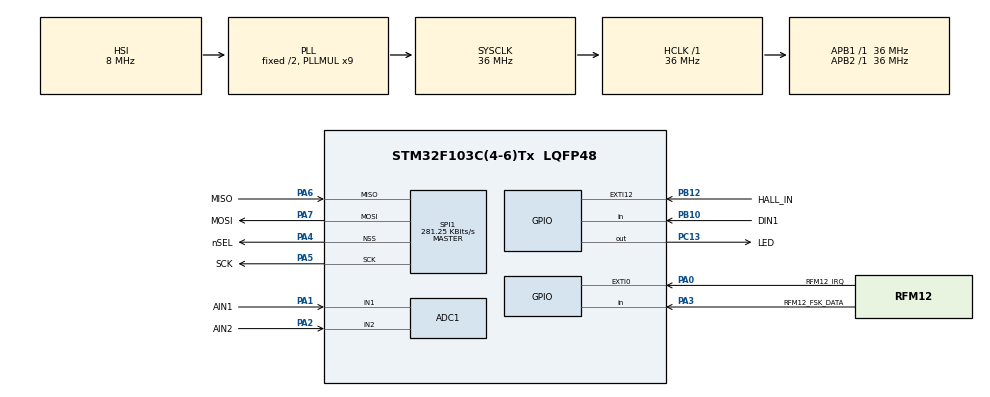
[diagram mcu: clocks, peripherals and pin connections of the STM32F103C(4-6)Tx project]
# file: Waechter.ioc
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ADC1.Channel-0\#ChannelRegularConversion=ADC_CHANNEL_1
ADC1.NbrOfConversionFlag=1
ADC1.Rank-0\#ChannelRegularConversion=1
ADC1.SamplingTime-0\#ChannelRegularConversion=ADC_SAMPLETIME_1CYCLE_5
ADC1.master=1
Mcu.Family=STM32F1
Mcu.Name=STM32F103C(4-6)Tx
Mcu.Package=LQFP48
NVIC.EXTI0_IRQn=true\:0\:0\:false\:false\:true
NVIC.PriorityGroup=NVIC_PRIORITYGROUP_4
PA0-WKUP.GPIO_Label=RFM12_IRQ
PA0-WKUP.GPIO_PuPd=GPIO_PULLUP
PA0-WKUP.Signal=GPXTI0
PA1.GPIO_Label=AIN1
PA1.Signal=ADCx_IN1
PA13.Mode=JTAG_4_pins
PA13.Signal=SYS_JTMS-SWDIO
PA14.Mode=JTAG_4_pins
PA14.Signal=SYS_JTCK-SWCLK
PA15.Mode=JTAG_4_pins
PA15.Signal=SYS_JTDI
PA2.GPIO_Label=AIN2
PA2.Signal=ADCx_IN2
PA3.GPIO_Label=RFM12_FSK_DATA
PA3.GPIO_PuPd=GPIO_PULLUP
PA3.Signal=GPIO_Input
PA4.GPIO_Label=nSEL
PA4.Mode=NSS_Signal_Hard_Output
PA4.Signal=SPI1_NSS
PA5.GPIO_Label=SCK
PA5.Mode=Full_Duplex_Master
PA5.Signal=SPI1_SCK
PA6.GPIO_Label=MISO
PA6.Mode=Full_Duplex_Master
PA6.Signal=SPI1_MISO
PA7.GPIO_Label=MOSI
PA7.Mode=Full_Duplex_Master
PA7.Signal=SPI1_MOSI
PB10.GPIO_Label=DIN1
PB10.Signal=GPIO_Input
PB12.GPIO_Label=HALL_IN
PB12.Signal=GPXTI12
PB3.Mode=JTAG_4_pins
PB3.Signal=SYS_JTDO-TRACESWO
PC13-TAMPER-RTC.GPIO_Label=LED
PC13-TAMPER-RTC.GPIO_Speed=GPIO_SPEED_FREQ_HIGH
PC13-TAMPER-RTC.Signal=GPIO_Output
ProjectManager.HeapSize=0x200
ProjectManager.StackSize=0x400
ProjectManager.TargetToolchain=MDK-ARM V5
RCC.ADCPresc=RCC_ADCPCLK2_DIV8
RCC.AHBFreq_Value=36000000
RCC.APB1Freq_Value=36000000
RCC.APB1TimFreq_Value=36000000
RCC.APB2Freq_Value=36000000
RCC.APB2TimFreq_Value=36000000
RCC.HCLKFreq_Value=36000000
RCC.PLLMUL=RCC_PLL_MUL9
RCC.SYSCLKFreq_VALUE=36000000
RCC.SYSCLKSource=RCC_SYSCLKSOURCE_PLLCLK
RCC.USBFreq_Value=36000000
RCC.VDD_VALUE=3.3
SH.ADCx_IN1.0=ADC1_IN1,IN1
SH.ADCx_IN2.0=ADC1_IN2,IN2
SPI1.BaudRatePrescaler=SPI_BAUDRATEPRESCALER_128
SPI1.CalculateBaudRate=281.25 KBits/s
SPI1.DataSize=SPI_DATASIZE_16BIT
SPI1.Mode=SPI_MODE_MASTER
SPI1.VirtualNSS=VM_NSSHARD
board=Waechter

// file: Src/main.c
/**
  ******************************************************************************
  * File Name          : main.c
  * Description        : Main program body
  ******************************************************************************
  *
  * COPYRIGHT(c) 2017 STMicroelectronics
  *
  * Redistribution and use in source and binary forms, with or without modification,
  * are permitted provided that the following conditions are met:
  *   1. Redistributions of source code must retain the above copyright notice,
  *      this list of conditions and the following disclaimer.
  *   2. Redistributions in binary form must reproduce the above copyright notice,
  *      this list of conditions and the following disclaimer in the documentation
  *      and/or other materials provided with the distribution.
  *   3. Neither the name of STMicroelectronics nor the names of its contributors
  *      may be used to endorse or promote products derived from this software
  *      without specific prior written permission.
  *
  * THIS SOFTWARE IS PROVIDED BY THE COPYRIGHT HOLDERS AND CONTRIBUTORS "AS IS"
  * AND ANY EXPRESS OR IMPLIED WARRANTIES, INCLUDING, BUT NOT LIMITED TO, THE
  * IMPLIED WARRANTIES OF MERCHANTABILITY AND FITNESS FOR A PARTICULAR PURPOSE ARE
  * DISCLAIMED. IN NO EVENT SHALL THE COPYRIGHT HOLDER OR CONTRIBUTORS BE LIABLE
  * FOR ANY DIRECT, INDIRECT, INCIDENTAL, SPECIAL, EXEMPLARY, OR CONSEQUENTIAL
  * DAMAGES (INCLUDING, BUT NOT LIMITED TO, PROCUREMENT OF SUBSTITUTE GOODS OR
  * SERVICES; LOSS OF USE, DATA, OR PROFITS; OR BUSINESS INTERRUPTION) HOWEVER
  * CAUSED AND ON ANY THEORY OF LIABILITY, WHETHER IN CONTRACT, STRICT LIABILITY,
  * OR TORT (INCLUDING NEGLIGENCE OR OTHERWISE) ARISING IN ANY WAY OUT OF THE USE
  * OF THIS SOFTWARE, EVEN IF ADVISED OF THE POSSIBILITY OF SUCH DAMAGE.
  *
  ******************************************************************************
  */
#include "main.h"
#include "stm32f1xx_hal.h"

ADC_HandleTypeDef hadc1;

SPI_HandleTypeDef hspi1;

/* USER CODE BEGIN PV */
/* Private variables ---------------------------------------------------------*/

/* USER CODE END PV */

void SystemClock_Config(void);
void Error_Handler(void);
static void MX_GPIO_Init(void);
static void MX_ADC1_Init(void);
static void MX_SPI1_Init(void);

/* USER CODE BEGIN PFP */
/* Private function prototypes -----------------------------------------------*/
void  Waechter_Init(void);
void  Waechter_Main(void);

/* USER CODE END PFP */

/* USER CODE BEGIN 0 */
//#define SIMULATOR 1

/* USER CODE END 0 */

int main(void)
{

  /* MCU Configuration----------------------------------------------------------*/

  /* Reset of all peripherals, Initializes the Flash interface and the Systick. */
  HAL_Init();

  /* Configure the system clock */
  SystemClock_Config();

  /* Initialize all configured peripherals */
  MX_GPIO_Init();
  MX_ADC1_Init();
  MX_SPI1_Init();

  /* USER CODE BEGIN 2 */
  Waechter_Init();

  /* USER CODE END 2 */

  /* Infinite loop */
  /* USER CODE BEGIN WHILE */
  while (1)
  {
    Waechter_Main();
  /* USER CODE END WHILE */

  }

}

/** System Clock Configuration
*/
void SystemClock_Config(void)
{

  RCC_OscInitTypeDef RCC_OscInitStruct;
  RCC_ClkInitTypeDef RCC_ClkInitStruct;
  RCC_PeriphCLKInitTypeDef PeriphClkInit;

    /**Initializes the CPU, AHB and APB busses clocks
    */
  RCC_OscInitStruct.OscillatorType = RCC_OSCILLATORTYPE_HSI;
  RCC_OscInitStruct.HSIState = RCC_HSI_ON;
  RCC_OscInitStruct.HSICalibrationValue = 16;
  RCC_OscInitStruct.PLL.PLLState = RCC_PLL_ON;
  RCC_OscInitStruct.PLL.PLLSource = RCC_PLLSOURCE_HSI_DIV2;
  RCC_OscInitStruct.PLL.PLLMUL = RCC_PLL_MUL9;
#ifndef SIMULATOR
  if (HAL_RCC_OscConfig(&RCC_OscInitStruct) != HAL_OK)
  {
    Error_Handler();
  }
#endif

    /**Initializes the CPU, AHB and APB busses clocks
    */
  RCC_ClkInitStruct.ClockType = RCC_CLOCKTYPE_HCLK|RCC_CLOCKTYPE_SYSCLK
                              |RCC_CLOCKTYPE_PCLK1|RCC_CLOCKTYPE_PCLK2;
  RCC_ClkInitStruct.SYSCLKSource = RCC_SYSCLKSOURCE_PLLCLK;
  RCC_ClkInitStruct.AHBCLKDivider = RCC_SYSCLK_DIV1;
  RCC_ClkInitStruct.APB1CLKDivider = RCC_HCLK_DIV1;
  RCC_ClkInitStruct.APB2CLKDivider = RCC_HCLK_DIV1;

#ifndef SIMULATOR
  if (HAL_RCC_ClockConfig(&RCC_ClkInitStruct, FLASH_LATENCY_1) != HAL_OK)
  {
    Error_Handler();
  }
#endif

  PeriphClkInit.PeriphClockSelection = RCC_PERIPHCLK_ADC;
  PeriphClkInit.AdcClockSelection = RCC_ADCPCLK2_DIV8;
#ifndef SIMULATOR
  if (HAL_RCCEx_PeriphCLKConfig(&PeriphClkInit) != HAL_OK)
  {
    Error_Handler();
  }
#endif

    /**Configure the Systick interrupt time
    */
  HAL_SYSTICK_Config(HAL_RCC_GetHCLKFreq()/1000);

    /**Configure the Systick
    */
  HAL_SYSTICK_CLKSourceConfig(SYSTICK_CLKSOURCE_HCLK);

  /* SysTick_IRQn interrupt configuration */
  HAL_NVIC_SetPriority(SysTick_IRQn, 0, 0);
}

/* ADC1 init function */
static void MX_ADC1_Init(void)
{

  ADC_ChannelConfTypeDef sConfig;

    /**Common config
    */
  hadc1.Instance = ADC1;
  hadc1.Init.ScanConvMode = ADC_SCAN_DISABLE;
  hadc1.Init.ContinuousConvMode = DISABLE;
  hadc1.Init.DiscontinuousConvMode = DISABLE;
  hadc1.Init.ExternalTrigConv = ADC_SOFTWARE_START;
  hadc1.Init.DataAlign = ADC_DATAALIGN_RIGHT;
  hadc1.Init.NbrOfConversion = 1;
#ifndef SIMULATOR
  if (HAL_ADC_Init(&hadc1) != HAL_OK)
  {
    Error_Handler();
  }
#endif

    /**Configure Regular Channel
    */
  sConfig.Channel = ADC_CHANNEL_1;
  sConfig.Rank = 1;
  sConfig.SamplingTime = ADC_SAMPLETIME_1CYCLE_5;
#ifndef SIMULATOR
  if (HAL_ADC_ConfigChannel(&hadc1, &sConfig) != HAL_OK)
  {
    Error_Handler();
  }
#endif

}

/* SPI1 init function */
static void MX_SPI1_Init(void)
{

  hspi1.Instance = SPI1;
  hspi1.Init.Mode = SPI_MODE_MASTER;
  hspi1.Init.Direction = SPI_DIRECTION_2LINES;
  hspi1.Init.DataSize = SPI_DATASIZE_16BIT;
  hspi1.Init.CLKPolarity = SPI_POLARITY_LOW;
  hspi1.Init.CLKPhase = SPI_PHASE_1EDGE;
  hspi1.Init.NSS = SPI_NSS_HARD_OUTPUT;
  hspi1.Init.BaudRatePrescaler = SPI_BAUDRATEPRESCALER_128;
  hspi1.Init.FirstBit = SPI_FIRSTBIT_MSB;
  hspi1.Init.TIMode = SPI_TIMODE_DISABLE;
  hspi1.Init.CRCCalculation = SPI_CRCCALCULATION_DISABLE;
  hspi1.Init.CRCPolynomial = 10;
#ifndef SIMULATOR
  if (HAL_SPI_Init(&hspi1) != HAL_OK)
  {
    Error_Handler();
  }
#endif

}

/** Configure pins as
        * Analog
        * Input
        * Output
        * EVENT_OUT
        * EXTI
*/
static void MX_GPIO_Init(void)
{

  GPIO_InitTypeDef GPIO_InitStruct;

  /* GPIO Ports Clock Enable */
  __HAL_RCC_GPIOC_CLK_ENABLE();
  __HAL_RCC_GPIOA_CLK_ENABLE();
  __HAL_RCC_GPIOB_CLK_ENABLE();

  /*Configure GPIO pin Output Level */
  HAL_GPIO_WritePin(LED_GPIO_Port, LED_Pin, GPIO_PIN_RESET);

  /*Configure GPIO pin : LED_Pin */
  GPIO_InitStruct.Pin = LED_Pin;
  GPIO_InitStruct.Mode = GPIO_MODE_OUTPUT_PP;
  GPIO_InitStruct.Speed = GPIO_SPEED_FREQ_HIGH;
  HAL_GPIO_Init(LED_GPIO_Port, &GPIO_InitStruct);

  /*Configure GPIO pin : RFM12_IRQ_Pin */
  GPIO_InitStruct.Pin = RFM12_IRQ_Pin;
  GPIO_InitStruct.Mode = GPIO_MODE_IT_RISING;
  GPIO_InitStruct.Pull = GPIO_PULLUP;
  HAL_GPIO_Init(RFM12_IRQ_GPIO_Port, &GPIO_InitStruct);

  /*Configure GPIO pin : RFM12_FSK_DATA_Pin */
  GPIO_InitStruct.Pin = RFM12_FSK_DATA_Pin;
  GPIO_InitStruct.Mode = GPIO_MODE_INPUT;
  GPIO_InitStruct.Pull = GPIO_PULLUP;
  HAL_GPIO_Init(RFM12_FSK_DATA_GPIO_Port, &GPIO_InitStruct);

  /*Configure GPIO pin : DIN1_Pin */
  GPIO_InitStruct.Pin = DIN1_Pin;
  GPIO_InitStruct.Mode = GPIO_MODE_INPUT;
  GPIO_InitStruct.Pull = GPIO_NOPULL;
  HAL_GPIO_Init(DIN1_GPIO_Port, &GPIO_InitStruct);

  /*Configure GPIO pin : HALL_IN_Pin */
  GPIO_InitStruct.Pin = HALL_IN_Pin;
  GPIO_InitStruct.Mode = GPIO_MODE_IT_RISING;
  GPIO_InitStruct.Pull = GPIO_NOPULL;
  HAL_GPIO_Init(HALL_IN_GPIO_Port, &GPIO_InitStruct);

  /* EXTI interrupt init*/
  HAL_NVIC_SetPriority(EXTI0_IRQn, 0, 0);
  HAL_NVIC_EnableIRQ(EXTI0_IRQn);

}

void Error_Handler(void)
{
  while(1)
  {
  }
}

/************************ (C) COPYRIGHT STMicroelectronics *****END OF FILE****/
